AUTOSAR XML (schema 00049)
package /af_EvMsa_Component
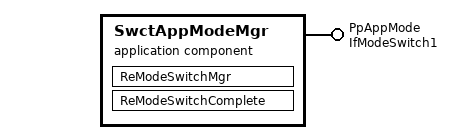
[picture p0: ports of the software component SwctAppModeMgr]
  application sw component type SwctAppModeMgr
    provide port PpAppMode: provided-interface=IfModeSwitch1
    behavior IbhSwctAppModeMgr
      runnable ReModeSwitchMgr
        mode switch point ModeSwitchPoint_PpAppMode: mode-group=PpAppMode.ECUMModePrototype1
      runnable ReModeSwitchComplete
      mode switched ack event EvMsaAppMode: start-on-event=ReModeSwitchComplete, event-source=ModeSwitchPoint_PpAppMode
